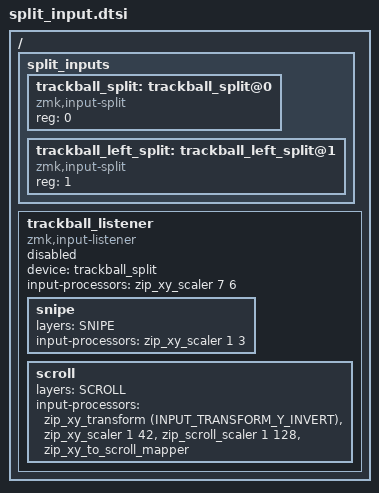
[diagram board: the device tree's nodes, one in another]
#include <dt-bindings/zmk/input_transform.h>
#include <input/processors.dtsi>

#define NONE	0
#define DEFAULT	0
#define COLEMAK	1
#define LOWER	2
#define RAISE	3
#define ADJUST	4
#define MOUSE   5
#define SCROLL  6
#define SNIPE   7
#define TEST	8

/ {
  split_inputs {
    #address-cells = <1>;
    #size-cells = <0>;

    trackball_split: trackball_split@0 {
      compatible = "zmk,input-split";
      reg = <0>;
    };

    trackball_left_split: trackball_left_split@1 {
      compatible = "zmk,input-split";
      reg = <1>;
    };
  };

  trackball_listener: trackball_listener {
    compatible = "zmk,input-listener";
    status = "disabled";
    device = <&trackball_split>;

    input-processors = <&zip_xy_scaler 7 6>;

    snipe {
      layers = <SNIPE>;
      input-processors = <&zip_xy_scaler 1 3>;
    };

    scroll {
      layers = <SCROLL>;
      input-processors = <
        &zip_xy_transform (INPUT_TRANSFORM_Y_INVERT)
        &zip_xy_scaler 1 42
				&zip_scroll_scaler 1 128
        &zip_xy_to_scroll_mapper
      >;
    };
  };

};


